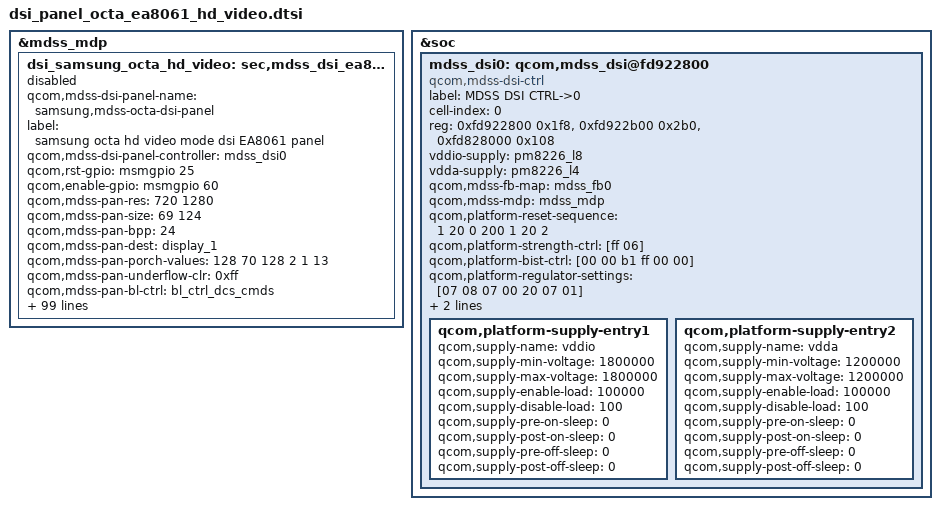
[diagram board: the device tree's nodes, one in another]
/* Copyright (c) 2012, Samsung Electronics Corporation. All rights reserved.
 *
 * This program is free software; you can redistribute it and/or modify
 * it under the terms of the GNU General Public License version 2 and
 * only version 2 as published by the Free Software Foundation.
 *
 * This program is distributed in the hope that it will be useful,
 * but WITHOUT ANY WARRANTY; without even the implied warranty of
 * MERCHANTABILITY or FITNESS FOR A PARTICULAR PURPOSE.  See the
 * GNU General Public License for more details.
 */

&mdss_mdp {
	dsi_samsung_octa_hd_video: sec,mdss_dsi_ea8061_hd_video {
		qcom,mdss-dsi-panel-name = "samsung,mdss-octa-dsi-panel";
		label = "samsung octa hd video mode dsi EA8061 panel";
		status = "disable";
		qcom,mdss-dsi-panel-controller = <&mdss_dsi0>;
		qcom,rst-gpio = <&msmgpio 25 0>;
		qcom,enable-gpio = <&msmgpio 60 0>;
		/*qcom,esd-irq-gpio =<&msmgpio 79 0x1>;*/
		qcom,mdss-pan-res = <720 1280>;
		qcom,mdss-pan-size = <69 124>; /* <Width> <Height> real size of panel in mm */
		qcom,mdss-pan-bpp = <24>;
		qcom,mdss-pan-dest = "display_1";
		qcom,mdss-pan-porch-values = <128 70 128 2 1 13>; /* <HBP> <HPW> <HFP> <VBP> <VPW> <VFP> */
		qcom,mdss-pan-underflow-clr = <0xff>;
		qcom,mdss-pan-bl-ctrl = "bl_ctrl_dcs_cmds";
		qcom,mdss-pan-bl-levels = <1 255>;
		qcom,mdss-pan-dsi-mode = <0>;
		qcom,mdss-pan-dsi-h-pulse-mode = <0>;
		qcom,mdss-pan-dsi-h-power-stop = <0 0 0>;
		qcom,mdss-pan-dsi-bllp-power-stop = <1 1>;
		qcom,mdss-pan-dsi-traffic-mode = <2>;
		qcom,mdss-pan-dsi-dst-format = <3>;
		qcom,mdss-pan-dsi-vc = <0>;
		qcom,mdss-pan-dsi-rgb-swap = <0>;
		qcom,mdss-force-clk-lane-hs = <1>;
		samsung,mdss-early-lcd-on = <0>;
		qcom,mdss-pan-dsi-data-lanes = <1 1 1 1>;
		qcom,mdss-pan-dsi-dlane-swap = <0>;
		qcom,mdss-pan-dsi-t-clk = <0x1b 0x04>;
		qcom,mdss-pan-dsi-stream = <0>;
		qcom,mdss-pan-dsi-mdp-tr = <0x0>;
		qcom,mdss-pan-dsi-dma-tr = <0x04>;
		qcom,mdss-pan-dsi-frame-rate = <60>;
		qcom,cont-splash-enabled;
		qcom,panel-phy-regulatorSettings = [07 09 03 00  /* Regualotor settings */
						    20 00 01];
		qcom,panel-phy-timingSettings = [96 27 20 00 39 3A 21 29 32 03 04 00];
		qcom,panel-phy-strengthCtrl = [ff 06];		/*!!!! */
		qcom,panel-phy-bistCtrl = [00 00 b1 ff           /*!!!! BIST Ctrl settings */
					   00 00];
		qcom,panel-phy-laneConfig = [
		00 00 00 00 00 00 00 01 97 /* lane0 config */
		00 00 00 00 05 00 00 01 97 /* lane1 config */
		00 00 00 00 0a 00 00 01 97 /* lane2 config */
		00 00 00 00 0f 00 00 01 97 /* lane3 config */
		00 c0 00 00 00 00 00 01 bb]; /* Clk ln config */

		qcom,panel-on-cmds = [
/*			Testkey Enable*/
			39 01 00 00 00 00 03 F0 5A 5A

/*			Common Setting*/
			39 01 00 00 00 00 03 F7 5A 5A

			39 01 00 00 00 00 20
				c4 41 87 41 87 49 77 49 77 00
				00 00 00 00 08 6e 00 00 10 05
				05 34 32 2d 00 00 03 02 00 01
				05 00

			39 01 00 00 00 00 03 F7 A5 A5
			39 01 00 00 00 00 02 36 02
			39 01 00 00 00 00 05 B3 00 05 00 05
			39 01 00 00 00 00 08 B2 0F B4 A0 00 00 00 00
			05 01 00 00 78 00 02 11 00

/*			Brightness Control*/
			39 01 00 00 00 00 03 F7 5A 5A

			39 01 00 00 00 00 21
				CA 01 00 01 00 01 00 80
				80 80 80 80 80 80 80 80
				80 80 80 80 80 80 80 80
				80 80 80 80 80 80 80 00
				00
			39 01 00 00 00 00 03 F7 A5 A5
			39 01 00 00 00 00 05 B3 00 05 00 05
			39 01 00 00 00 00 08 B2 0F B4 A0 00 00 00 00
			39 01 00 00 00 00 03 F1 5A 5A
			39 01 00 00 00 00 04 D4 18 00 48
			39 01 00 00 00 00 03 F1 A5 A5
			39 01 00 00 00 00 02 55 00

/*			ELVSS Control*/
			39 01 00 00 00 00 02 B0 06
			39 01 00 00 00 00 02 B2 19
			39 01 00 00 00 00 03 F1 5A 5A
			39 01 00 00 00 00 02 B0 02
			39 01 00 00 00 00 02 D4 48
			39 01 00 00 00 00 03 F1 A5 A5
			39 01 00 00 00 00 02 B2 0F

/*			ETC Condition*/
			39 01 00 00 00 00 03 F1 5A 5A
			39 01 00 00 00 00 02 B0 01
			39 01 00 00 00 00 02 D7 0A
			39 01 00 00 00 00 03 F1 A5 A5
			39 01 00 00 00 00 03 FC 5A 5A
			39 01 00 00 00 00 02 FF 31
			39 01 00 00 00 00 03 FC A5 A5

/*			Display on*/
			05 01 00 00 22 00 02 29 00
		];

		samsung,panel-manufacture-id-read-cmds = [
			06 01 00 00 00 00 01 DA 01 00
			06 01 00 00 00 00 01 DB 01 00
			06 01 00 00 00 00 01 DC 01 00
		];

		qcom,on-cmds-dsi-state = "dsi_lp_mode";
		qcom,panel-off-cmds = [
			05 01 00 00 22 00 02 28 00
			05 01 00 00 64 00 02 10 00
		];
		qcom,off-cmds-dsi-state = "dsi_hs_mode";
		samsung,panel-acl-off-cmds = [39 01 00 00 72 00 02 55 00];
		/*
		the last byte in read commands  represent READ LENGH,
		like below  READ LENGH = 0x21
		*/

		samsung,panel-mtp-read-cmds = [ 39 01 00 00 00 00 03 FD DA 00 ];
		samsung,panel-nv-mtp-read-cmds = [ 06 01 00 00 00 00 01 FE 20 00];
		samsung,panel-nv-mtp-read-hbm-cmds = [ 06 01 00 00 00 00 01 FE 15 00];	/* read DB 01~21th , 01=0x01*/
		samsung,panel-nv-mtp-read-hbm2-cmds = [ 06 01 00 00 00 00 01 FE 01 21];	/* read DB 34th , 34=0x22*/
		samsung,panel-nv-mtp-read-hbm3-cmds = [ 06 01 00 00 00 00 01 D4 01 12];	/* read D4 18th , 18=0x12*/
		samsung,panel-nv-mdnie-read-cmds = [ 06 01 00 00 00 00 01 A1 04 00];
		samsung,panel-nv-read-cmds = [ 06 01 00 00 00 00 01 FE 20 00];
		samsung,panel-test-key-enable-cmds = [ 39 01 00 00 00 00 03 F0 5A 5A];
		samsung,panel-test-key-disable-cmds = [ 39 01 00 00 00 00 03 F0 A5 A5];
		samsung,panel-nv-read-enable-cmds = [
							39 01 00 00 00 00 03 F0 5A 5A
							39 01 00 00 00 00 03 F1 5A 5A
							39 01 00 00 00 00 03 FC 5A 5A];
		samsung,panel-nv-read-disable-cmds = [
							39 01 00 00 00 00 03 F0 A5 A5
							39 01 00 00 00 00 03 F1 A5 A5
							39 01 00 00 00 00 03 FC A5 A5 ];

		samsung,panel-gamma-hbm-cmds-list = [
					39 01 00 00 01 00 03 F7 5A 5A
					39 01 00 00 01 00 21
					CA 01 00 01 00 01 00 80
					80 80 80 80 80 80 80 80
					80 80 80 80 80 80 80 80
					80 80 80 80 80 80 80 00
					00
					39 01 00 00 01 00 03 F7 A5 A5];
		samsung,panel-etc-hbm-cmds = [
					39 01 00 00 00 00 05 B3 00 05 00 05	/* samsung_brightness_aor_condition */
					39 01 00 00 01 00 08 B2 0F B4 A0 00 00 00 00
					39 01 00 00 00 00 03 F1 5A 5A
					39 01 00 00 00 00 1F D4 38 00 48 00 00 00 00 00	/* ELVSS  */
						00 00 00 00 00 60 66 C6 0C 00 00 00 00 00 00 00 00 00 00 00 00 00
					39 01 00 00 00 00 03 F1 A5 A5
					39 01 00 00 01 00 02 55 02
				];

		qcom,panel-display-on-cmds = [05 01 00 00 32 00 02 29 00];
		qcom,panel-display-off-cmds = [05 01 00 00 32 00 02 28 00];

		qcom,panel-display-unblank-cmds = [05 01 00 00 32 00 02 13 00];			/*Normal mode command*/
		qcom,panel-display-blank-cmds = [05 01 00 00 45 00 02 22 00];		 /* All pixel off*/
		samsung,panel-hbm-off-elvss-cmds = [
					39 01 00 00 00 00 03 F0 5A 5A
					39 01 00 00 01 00 03 F7 5A 5A
					39 01 00 00 01 00 21
					CA 01 00 01 00 01 00 80
					80 80 80 80 80 80 80 80
					80 80 80 80 80 80 80 80
					80 80 80 80 80 80 80 00
					00
					39 01 00 00 01 00 03 F7 A5 A5
					39 01 00 00 00 00 03 F1 5A 5A
					39 01 00 00 00 00 1F D4 38 00 48 00 00 00 00 00	/* ELVSS  */
						00 00 00 00 00 60 66 C6 0C 00 00 00 00 00 00 00 00 00 00 00 00 00
					39 01 00 00 00 00 03 F1 A5 A5
					39 01 00 00 00 00 03 F0 A5 A5
		];

		samsung,panel-elvss-lowtemp-cmds-list = [
							39 01 00 00 00 00 02 B0 05
							39 01 00 00 00 00 02 B8 00
							39 01 00 00 00 00 02 B6 8C];	/* Low Temperature Command */
		samsung,panel-skew-control-cmds = [ 39 01 00 00 00 00 04 B4 33 0A 00 ];

		/*
		* ************************************************************************************************************************
		* AID command list and mappings
		* ************************************************************************************************************************
		*/

		samsung,panel-aid-cmds-list-350 = [
			39 01 00 00 00 00 05 B3 00 05 00 05 /* 0 samsung_brightness_aor_0p4 */
			39 01 00 00 00 00 05 B3 00 05 00 70 /* 1 samsung_brightness_aor_19p8 */
			39 01 00 00 00 00 05 B3 00 05 00 B3 /* 2 samsung_brightness_aor_34p1 */
			39 01 00 00 00 00 05 B3 00 05 01 01 /* 3 samsung_brightness_aor_24p8 */
			39 01 00 00 00 00 05 B3 00 05 01 45 /* 4 samsung_brightness_aor_10p6 */
			39 01 00 00 00 00 05 B3 00 05 01 7D /* 5 samsung_brightness_aor_8p6 */
			39 01 00 00 00 00 05 B3 00 05 01 BA /* 6 samsung_brightness_aor_25p1 */
			39 01 00 00 00 00 05 B3 00 05 01 E0 /* 7 samsung_brightness_aor_35p0 */
			39 01 00 00 00 00 05 B3 00 05 02 07 /* 8 samsung_brightness_aor_38p2 */
			39 01 00 00 00 00 05 B3 00 05 02 27 /* 9 samsung_brightness_aor_42p5 */
			39 01 00 00 00 00 05 B3 00 05 02 57 /* 10 samsung_brightness_aor_46p2 */
			39 01 00 00 00 00 05 B3 00 05 02 88 /* 11 samsung_brightness_aor_50p0 */
			39 01 00 00 00 00 05 B3 00 05 02 AC /* 12 samsung_brightness_aor_52p8 */
			39 01 00 00 00 00 05 B3 00 05 02 CE /* 13 samsung_brightness_aor_55p4 */
			39 01 00 00 00 00 05 B3 00 05 02 F6 /* 14 samsung_brightness_aor_58p5 */
			39 01 00 00 00 00 05 B3 00 05 03 17 /* 15 samsung_brightness_aor_61p0 */
			39 01 00 00 00 00 05 B3 00 05 03 3D /* 16 samsung_brightness_aor_64p0 */
			39 01 00 00 00 00 05 B3 00 05 03 45 /* 17 samsung_brightness_aor_64p6 */
			39 01 00 00 00 00 05 B3 00 05 03 54 /* 18 samsung_brightness_aor_65p7 */
			39 01 00 00 00 00 05 B3 00 05 03 6B /* 19 samsung_brightness_aor_67p5 */
			39 01 00 00 00 00 05 B3 00 05 03 8C /* 20 samsung_brightness_aor_70p1 */
			39 01 00 00 00 00 05 B3 00 05 03 A5 /* 21 samsung_brightness_aor_72p0 */
			39 01 00 00 00 00 05 B3 00 05 03 BD /* 22 samsung_brightness_aor_73p8 */
			39 01 00 00 00 00 05 B3 00 05 03 CE /* 23 samsung_brightness_aor_75p2 */
			39 01 00 00 00 00 05 B3 00 05 03 DF /* 24 samsung_brightness_aor_76p5 */
			39 01 00 00 00 00 05 B3 00 05 03 F4 /* 25 samsung_brightness_aor_78p1 */
			39 01 00 00 00 00 05 B3 00 05 04 01 /* 26 samsung_brightness_aor_79p1 */
			39 01 00 00 00 00 05 B3 00 05 04 19 /* 27 samsung_brightness_aor_80p9 */
			39 01 00 00 00 00 05 B3 00 05 04 23 /* 28 samsung_brightness_aor_81p7 */
			39 01 00 00 00 00 05 B3 00 05 04 2F /* 29 samsung_brightness_aor_82p6 */
			39 01 00 00 00 00 05 B3 00 05 04 41 /* 30 samsung_brightness_aor_84p0 */
			39 01 00 00 00 00 05 B3 00 05 04 57 /* 31 samsung_brightness_aor_85p7 */
			39 01 00 00 00 00 05 B3 00 05 04 60 /* 32 samsung_brightness_aor_86p4 */
			39 01 00 00 00 00 05 B3 00 05 04 6C /* 33 samsung_brightness_aor_87p3 */
			39 01 00 00 00 00 05 B3 00 05 04 77 /* 34 samsung_brightness_aor_88p2 */
			39 01 00 00 00 00 05 B3 00 05 04 83 /* 35 samsung_brightness_aor_89p1 */
			39 01 00 00 00 00 05 B3 00 05 04 8D /* 36 samsung_brightness_aor_89p9 */
			39 01 00 00 00 00 05 B3 00 05 04 98 /* 37 samsung_brightness_aor_90p7 */
			39 01 00 00 00 00 05 B3 00 05 04 A1 /* 38 samsung_brightness_aor_91p4 */
			39 01 00 00 00 00 05 B3 00 05 04 AD /* 39 samsung_brightness_aor_92p4 */
			39 01 00 00 00 00 05 B3 00 05 04 B9 /* 40 samsung_brightness_aor_93p3 */
			39 01 00 00 00 00 05 B3 00 05 04 C3 /* 41 samsung_brightness_aor_94p1 */
			39 01 00 00 00 00 05 B3 00 05 04 CE /* 42 samsung_brightness_aor_94p9 */
			39 01 00 00 00 00 05 B3 00 05 04 D9 /* 43 samsung_brightness_aor_95p8 */
			39 01 00 00 00 00 05 B3 00 05 04 E2 /* 44 samsung_brightness_aor_96p5 */
			39 01 00 00 00 00 05 B3 00 05 04 ED /* 45 samsung_brightness_aor_97p3 */
			39 01 00 00 00 00 05 B3 00 05 04 F4 /* 46 samsung_brightness_aor_97p3 */
			39 01 00 00 00 00 05 B3 00 05 04 F7 /* 47 samsung_brightness_aor_97p8 */
			39 01 00 00 00 00 05 B3 00 05 04 FA /* 48 samsung_brightness_aor_97p8 */
			39 01 00 00 00 00 05 B3 00 05 04 FD /* 49 samsung_brightness_aor_97p8 */
			39 01 00 00 00 00 05 B3 00 05 05 01 /* 50 samsung_brightness_aor_97p8 */
			39 01 00 00 00 00 05 B3 00 05 05 03 /* 51 samsung_brightness_aor_97p8 */
			39 01 00 00 00 00 05 B3 00 05 05 05 /* 52 samsung_brightness_aor_97p8 */
			39 01 00 00 00 00 05 B3 00 05 05 08 /* 53 samsung_brightness_aor_97p8 */
			39 01 00 00 00 00 05 B3 00 05 05 0B /* 54 samsung_brightness_aor_97p8 */
		];

		samsung,panel-aid-map-table = <
			2   54         3   53       4    52        5   51      6   50
			7   49         8   48       9    47        10   46      11   45
			12   45        13   45       14   44       15   44     16   44
			17   43        19   43       20   43       21   43     22   42
			24   42        25   41       27   41       29   40     30   40
			32   39        34   39       37   38       39   38
			41   37        44   37       47   36       50   36     53   35
			56   35        60  34       64   34       68   33
			72   33        77   32       82   32     87   31
			93  31        98  30       105  30     106 29
			107  28         108  27        109  26        110  25      111  24
			119  23         126  22        134  21        143  20      152  19
			162  18         172  17        173  16        175  15	   177	14
			179	 13		   181  12		 183  11		   195	10	   207  9
			220	 8		   234	7		 249  6		   265	5	   282  4
			300	 3		   316  2		   333  1		   350  0
		>;

		/*
		* ************************************************************************************************************************
		* ACL command list and mappings
		* ************************************************************************************************************************
		*/
		samsung,panel-aclcont-cmds-list = [
			39 01 00 00 00 00 07 B5 03 99 27 1F 45 0A];	/* ACL Condition */
		samsung,panel-acl-cmds-list = [
			39 01 00 00 00 00 02 55 00
			39 01 00 00 00 00 02 55 01
			39 01 00 00 00 00 02 55 02 /* ACL 25% */
			39 01 00 00 00 00 02 55 03];

		/* bl_level , Index in acl command list */
		samsung,panel-acl-map-table =  <
			2    2          3   2        4    2    5   2       6   2
			7    2          8   2        9    2    10   2       11   2
			12   2         13   2        14   2   15   2      16   2
			17   2         19   2        20   2   21   2      22   2
			24   2         25   2        27   2   29   2      30   2
			32   2         34   2        37   2   39   2
			41   2         44   2        47   2   50   2      53   2
			56   2         60   2        64   2   68   2
			72   2         77   2        82   2      87   2
			 93  2        98  2   105  2      106  2
			107  2         108  2        109  2   110  2      111  2
			119  2         126  2        134  2   143  2      152  2
			162	 2		   172 2        173 2     175  2      177  2
			179  2         181  2        183  2   195  2      207  2
			220  2         234  2        249  2   265  2	  282  2
			300  2		   316  2		   333  2		   350  2
		>;

		/*
		* ************************************************************************************************************************
		* ELVSS(ACL Off) command list and mappings
		* ************************************************************************************************************************
		*/
		samsung,panel-elvss-cmds-list = [
			39 01 00 00 00 00 02 B2 21  /* 0 DEFAULT_ELVSS(0x21) */
			39 01 00 00 00 00 02 B2 20  /* 1 DEFAULT_ELVSS(0x20) */
			39 01 00 00 00 00 02 B2 1F  /* 2 DEFAULT_ELVSS(0x1F) */
			39 01 00 00 00 00 02 B2 1E  /* 3 DEFAULT_ELVSS(0x1E) */
			39 01 00 00 00 00 02 B2 1D  /* 4 DEFAULT_ELVSS(0x1D) */
			39 01 00 00 00 00 02 B2 1C  /* 5 DEFAULT_ELVSS(0x1C) */
			39 01 00 00 00 00 02 B2 1B  /* 6 DEFAULT_ELVSS(0x1B) */
			39 01 00 00 00 00 02 B2 1A  /* 7 DEFAULT_ELVSS(0x1B) */
			39 01 00 00 00 00 02 B2 18  /* 8 DEFAULT_ELVSS(0x18) */
			39 01 00 00 00 00 02 B2 17  /* 9 DEFAULT_ELVSS(0x17) */
			39 01 00 00 00 00 02 B2 19  /* 10 DEFAULT_ELVSS(0x19) */
			39 01 00 00 00 00 02 B2 1A  /* 11 DEFAULT_ELVSS(0x1A) */
			39 01 00 00 00 00 02 B2 1C  /* 12 DEFAULT_ELVSS(0x1C) */
			39 01 00 00 00 00 02 B2 1B  /* 13 DEFAULT_ELVSS(0x1B) */
			39 01 00 00 00 00 02 B2 1A  /* 14 DEFAULT_ELVSS(0x1A) */
			39 01 00 00 00 00 02 B2 19  /* 15 DEFAULT_ELVSS(0x19) */
			39 01 00 00 00 00 02 B2 18  /* 16 DEFAULT_ELVSS(0x18) */
			39 01 00 00 00 00 02 B2 17  /* 17 DEFAULT_ELVSS(0x17) */
			39 01 00 00 00 00 02 B2 16  /* 18 DEFAULT_ELVSS(0x16) */
			39 01 00 00 00 00 02 B2 14 /* 19 DEFAULT_ELVSS(0x14) */
			39 01 00 00 00 00 02 B2 13  /* 20 DEFAULT_ELVSS(0x13) */
			39 01 00 00 00 00 02 B2 12  /* 21 DEFAULT_ELVSS(0x12) */
			39 01 00 00 00 00 02 B2 10  /* 22 DEFAULT_ELVSS(0x10) */
			39 01 00 00 00 00 02 B2 0F  /* 23 DEFAULT_ELVSS(0x0F) */
		];

		/* bl_level, Index in elvss command list */
		samsung,panel-elvss-map-table = <
			2	0	3	0	4	0	5	0	6	0
			7	0	8	0	9	0	10	0	11	0
			12	0	13	0	14	0	15	0	16	0
			17	0	19	0	20	0	21	0	22	0
			24	0	25	0	27	0	29	0	30	0
			32	0	34	0	37	0	39	0
			41	0	44	0	47	0	50	0	53	0
			56	0	60	0	64	0	68	0
			72	0	77	0	82	0	87	0
			93	0	98	0	105	0	106	1
			107	2	108 2   109	2	110	2	111	3
			119	3	126	4	134	5	143	6	152	7
			162	8	172	9	173	10	175	10	177	10
			179	10	181	11	183	12	195	13	207	14
			220	15	234	16	249	17	265	18	282	19
			300	20	316	21	333	22	350	23
		>;

		/*
		* ************************************************************************************************************************
		* SMART ACL(ACL On) ELVSS command list and mappings
		* ************************************************************************************************************************
		*/
		samsung,panel-smart-acl-elvss-cmds-list = [
			39 01 00 00 00 00 02 B2 21  /* 0 DEFAULT_ELVSS(0x21) */
			39 01 00 00 00 00 02 B2 20  /* 1 DEFAULT_ELVSS(0x20) */
			39 01 00 00 00 00 02 B2 1F  /* 2 DEFAULT_ELVSS(0x1F) */
			39 01 00 00 00 00 02 B2 1E  /* 3 DEFAULT_ELVSS(0x1E) */
			39 01 00 00 00 00 02 B2 1D  /* 4 DEFAULT_ELVSS(0x1D) */
			39 01 00 00 00 00 02 B2 1C  /* 5 DEFAULT_ELVSS(0x1C) */
			39 01 00 00 00 00 02 B2 1B  /* 6 DEFAULT_ELVSS(0x1B) */
			39 01 00 00 00 00 02 B2 1A  /* 7 DEFAULT_ELVSS(0x1B) */
			39 01 00 00 00 00 02 B2 18  /* 8 DEFAULT_ELVSS(0x18) */
			39 01 00 00 00 00 02 B2 17  /* 9 DEFAULT_ELVSS(0x17) */
			39 01 00 00 00 00 02 B2 19  /* 10 DEFAULT_ELVSS(0x19) */
			39 01 00 00 00 00 02 B2 1A  /* 11 DEFAULT_ELVSS(0x1A) */
			39 01 00 00 00 00 02 B2 1C  /* 12 DEFAULT_ELVSS(0x1C) */
			39 01 00 00 00 00 02 B2 1B  /* 13 DEFAULT_ELVSS(0x1B) */
			39 01 00 00 00 00 02 B2 1A  /* 14 DEFAULT_ELVSS(0x1A) */
			39 01 00 00 00 00 02 B2 19  /* 15 DEFAULT_ELVSS(0x19) */
			39 01 00 00 00 00 02 B2 18  /* 16 DEFAULT_ELVSS(0x18) */
			39 01 00 00 00 00 02 B2 17  /* 17 DEFAULT_ELVSS(0x17) */
			39 01 00 00 00 00 02 B2 16  /* 18 DEFAULT_ELVSS(0x16) */
			39 01 00 00 00 00 02 B2 14 /* 19 DEFAULT_ELVSS(0x14) */
			39 01 00 00 00 00 02 B2 13  /* 20 DEFAULT_ELVSS(0x13) */
			39 01 00 00 00 00 02 B2 12  /* 21 DEFAULT_ELVSS(0x12) */
			39 01 00 00 00 00 02 B2 10  /* 22 DEFAULT_ELVSS(0x10) */
			39 01 00 00 00 00 02 B2 0F  /* 23 DEFAULT_ELVSS(0x0F) */
		];

		/* bl_level, Index in elvss command list */
		samsung,panel-smart-acl-elvss-map-table = <
			2	0	3	0	4	0	5	0	6	0
			7	0	8	0	9	0	10	0	11	0
			12	0	13	0	14	0	15	0	16	0
			17	0	19	0	20	0	21	0	22	0
			24	0	25	0	27	0	29	0	30	0
			32	0	34	0	37	0	39	0
			41	0	44	0	47	0	50	0	53	0
			56	0	60	0	64	0	68	0
			72	0	77	0	82	0	87	0
			93	0	98	0	105	0	106	1
			107	1	108 2   109	2	110	2	111	3
			119	3	126	4	134	5	143	6	152	7
			162	8	172	9	173	10	175	10	177	10
			179	10	181	11	183	12	195	13	207	14
			220	15	234	16	249	17	265	18	282	19
			300	20	316	21	333	22	350	23
		>;

		/*
		* ************************************************************************************************************************
		* candela to index mappings
		* ************************************************************************************************************************
		*/
		samsung,panel-candella-mapping-table-350 = <
		/*<idx>	  <from>  <till> <candella> */
			0		0		2		2
			1		3		3		3
			2		4		4		4
			3		5		5		5
			4		6		6		6
			5		7		7		7
			6		8		8		8
			7		9		9		9
			8		10		10		10
			9		11		11		11
			10		12		12		12
			11		13		13		13
			12		14		14		14
			13		15		15		15
			14		16		16		16
			15		17		17		17
			16		18		18		19
			17		19		19		20
			18		20		20		21
			19		21		21		22
			20		22		22		24
			21		23		23		25
			22		24		25		27
			23		26		27		29
			24		28		29		30
			25		30		31		32
			26		32		33		34
			27		34		35		37
			28		36		37		39
			29		38		39		41
			30		40		41		44
			31		42		43		47
			32		44		45		50
			33		46		47		53
			34		48		49		56
			35		50		51		60
			36		52		53		64
			37		54		56		68
			38		57		59		72
			39		60		62		77
			40		63		65		82
			41		66		68		87
			42		69		72		93
			43		73		76		98
			44		77		81		105
			45		82		82		106
			46		83		83		107
			47		84		84		108
			48		85		85		109
			49		86		86		110
			50		87		87		111
			51		88		93		119
			52		94		98		126
			53		99		103		134
			54		104		108		143
			55		109		113		152
			56		114		119		162
			57		120		125		172
			58		126		127		173
			59		128		129		175
			60		130		131		177
			61		132		133		179
			62		134		138		181
			63		139		142		183
			64		143		151		195
			65		152		161		207
			66		162		171		220
			67		172		182		234
			68		183		194		249
			69		195		206		265
			70		207		218		282
			71		219		230		300
			72		231		242		316
			73		243		254		333
			74		255		255		350
		>;

		samsung,panel-gamma-cmds-list = [
			39 01 00 00 00 00 03
					F7 5A 5A  /* Gamma, LTPS(AID) update */
			39 01 00 00 00 00 21 /* Brightness Condition Set - Gamma 2.2 Setting*/
				ca 01 00 01 00 01 00 80
				80 80 80 80 80 80 80 80
				80 80 80 80 80 80 80 80
				80 80 80 80 80 80 80 00
				00
			39 01 00 00 00 00 03
					F7 A5 A5  /* Gamma, LTPS(AID) update */
		];
	};
};
&soc {
	mdss_dsi0: qcom,mdss_dsi@fd922800 {
		compatible = "qcom,mdss-dsi-ctrl";
		label = "MDSS DSI CTRL->0";
		cell-index = <0>;
		reg = 	<0xfd922800 0x1f8>,
			<0xfd922b00 0x2b0>,
			<0xfd828000 0x108>;
		reg-names = "dsi_ctrl", "dsi_phy", "mmss_misc_phys";
		vddio-supply = <&pm8226_l8>;
		vdda-supply = <&pm8226_l4>;
		qcom,mdss-fb-map = <&mdss_fb0>;
		qcom,mdss-mdp = <&mdss_mdp>;
		qcom,platform-reset-sequence = <1 20 0 200 1 20 2>;
		qcom,platform-strength-ctrl = [ff 06];
		qcom,platform-bist-ctrl = [00 00 b1 ff			 /*!!!! BIST Ctrl settings */
				   00 00];
		qcom,platform-regulator-settings = [07 08 07 00 20 07 01];
		qcom,platform-lane-config = [
		00 00 00 00 00 00 00 01 97 /* lane0 config */
		00 00 00 00 05 00 00 01 97 /* lane1 config */
		00 00 00 00 0a 00 00 01 97 /* lane2 config */
		00 00 00 00 0f 00 00 01 97 /* lane3 config */
		00 c0 00 00 00 00 00 01 bb]; /* Clk ln config */
		qcom,platform-supply-entry1 {
			qcom,supply-name = "vddio";
			qcom,supply-min-voltage = <1800000>;
			qcom,supply-max-voltage = <1800000>;
			qcom,supply-enable-load = <100000>;
			qcom,supply-disable-load = <100>;
			qcom,supply-pre-on-sleep = <0>;
			qcom,supply-post-on-sleep = <0>;
			qcom,supply-pre-off-sleep = <0>;
			qcom,supply-post-off-sleep = <0>;
		};
		qcom,platform-supply-entry2 {
			qcom,supply-name = "vdda";
			qcom,supply-min-voltage = <1200000>;
			qcom,supply-max-voltage = <1200000>;
			qcom,supply-enable-load = <100000>;
			qcom,supply-disable-load = <100>;
			qcom,supply-pre-on-sleep = <0>;
			qcom,supply-post-on-sleep = <0>;
			qcom,supply-pre-off-sleep = <0>;
			qcom,supply-post-off-sleep = <0>;
		};
	};
};
